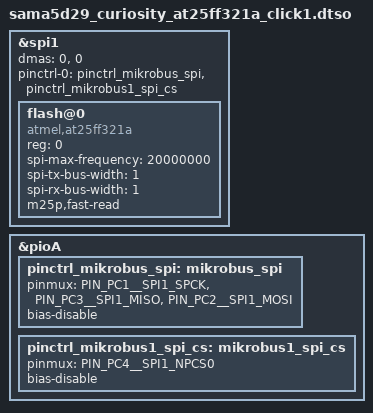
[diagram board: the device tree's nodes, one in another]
// SPDX-License-Identifier: (GPL-2.0+ OR MIT)
/*
 *  Device Tree overlay for SAMA5D29 CURIOSITY board
 *  in order to use SPI on click board 1 slot
 *
 *  Copyright (c) 2023 Microchip Technology Inc. and its subsidiaries
 *
 *  Author: Romain Sioen <romain.sioen@microchip.com>
 *
 */
/dts-v1/;
/plugin/;
#include "sama5d2-pinfunc.h"

&spi1 {
	#address-cells = <1>;
	#size-cells = <0>;
	dmas = <0>, <0>;
	pinctrl-names = "default";
	pinctrl-0 = <&pinctrl_mikrobus_spi &pinctrl_mikrobus1_spi_cs>;
	status = "okay";

	flash@0 {
		#address-cells = <1>;
		#size-cells = <1>;
		compatible = "atmel,at25ff321a", "jedec,spi-nor";
		reg = <0>;
		spi-max-frequency = <20000000>;
		spi-tx-bus-width = <1>;
		spi-rx-bus-width = <1>;
		m25p,fast-read;
	};
};

&pioA {
	pinctrl_mikrobus_spi: mikrobus_spi {
		pinmux = <PIN_PC1__SPI1_SPCK>,
			 <PIN_PC3__SPI1_MISO>,
			 <PIN_PC2__SPI1_MOSI>;
		bias-disable;
	};

	pinctrl_mikrobus1_spi_cs: mikrobus1_spi_cs {
		pinmux = <PIN_PC4__SPI1_NPCS0>;
		bias-disable;
	};
};

